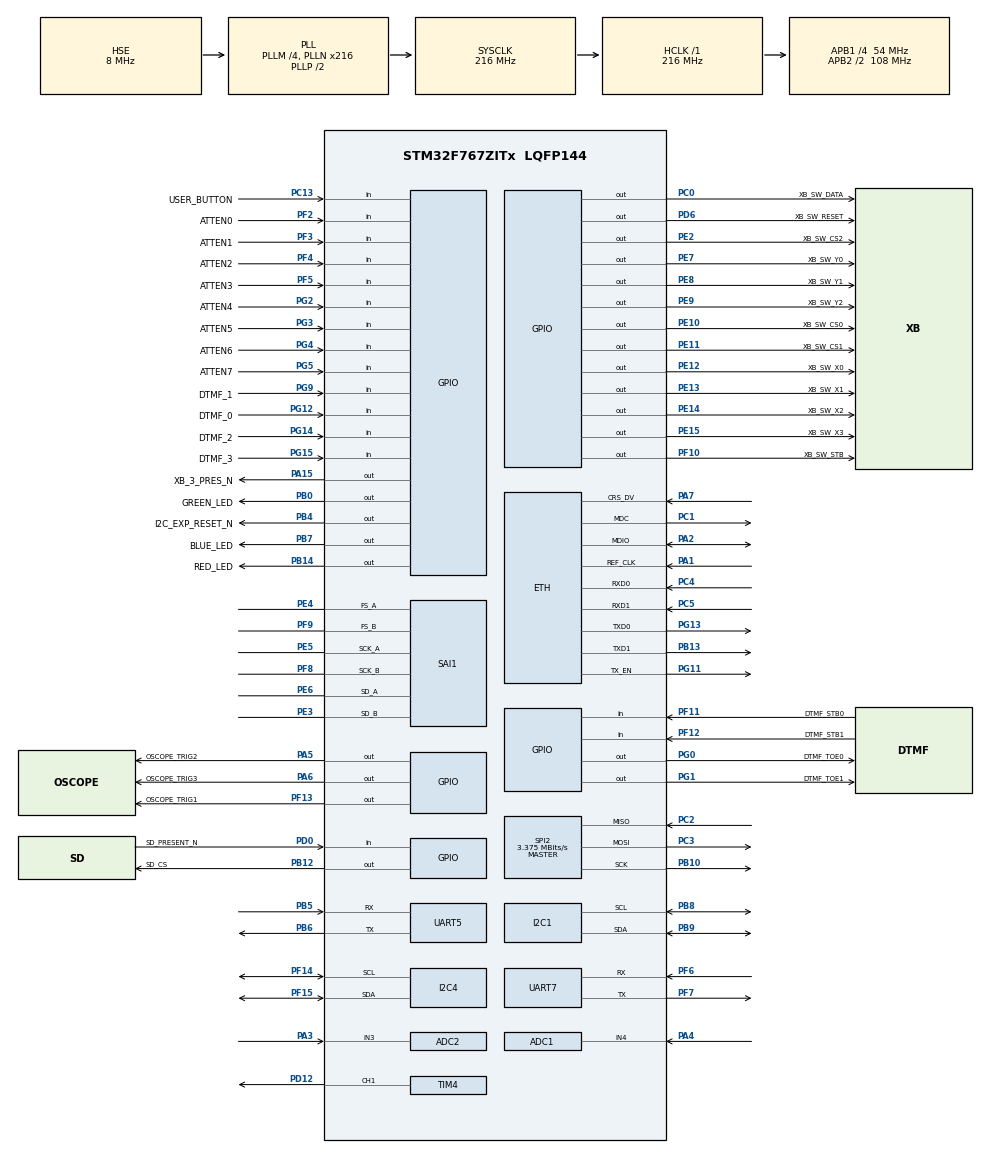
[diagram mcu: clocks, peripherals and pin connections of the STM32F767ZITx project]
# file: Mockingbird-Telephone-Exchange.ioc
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ADC1.Channel-1\#ChannelRegularConversion=ADC_CHANNEL_4
ADC1.DMAContinuousRequests=ENABLE
ADC1.EnableAnalogWatchDog=false
ADC1.ExternalTrigConv=ADC_EXTERNALTRIGCONV_T4_TRGO
ADC1.NbrOfConversionFlag=1
ADC1.Rank-1\#ChannelRegularConversion=1
ADC1.SamplingTime-1\#ChannelRegularConversion=ADC_SAMPLETIME_3CYCLES
ADC1.master=1
ADC2.Channel-0\#ChannelRegularConversion=ADC_CHANNEL_3
ADC2.DMAContinuousRequests=ENABLE
ADC2.EnableAnalogWatchDog=false
ADC2.ExternalTrigConv=ADC_EXTERNALTRIGCONV_T4_TRGO
ADC2.NbrOfConversionFlag=1
ADC2.Rank-0\#ChannelRegularConversion=1
ADC2.SamplingTime-0\#ChannelRegularConversion=ADC_SAMPLETIME_3CYCLES
Dma.ADC1.3.Direction=DMA_PERIPH_TO_MEMORY
Dma.ADC1.3.FIFOMode=DMA_FIFOMODE_DISABLE
Dma.ADC1.3.Instance=DMA2_Stream0
Dma.ADC1.3.MemDataAlignment=DMA_MDATAALIGN_HALFWORD
Dma.ADC1.3.MemInc=DMA_MINC_ENABLE
Dma.ADC1.3.Mode=DMA_CIRCULAR
Dma.ADC1.3.PeriphDataAlignment=DMA_PDATAALIGN_HALFWORD
Dma.ADC1.3.PeriphInc=DMA_PINC_DISABLE
Dma.ADC1.3.Priority=DMA_PRIORITY_LOW
Dma.ADC2.2.Direction=DMA_PERIPH_TO_MEMORY
Dma.ADC2.2.FIFOMode=DMA_FIFOMODE_DISABLE
Dma.ADC2.2.Instance=DMA2_Stream2
Dma.ADC2.2.MemDataAlignment=DMA_MDATAALIGN_HALFWORD
Dma.ADC2.2.MemInc=DMA_MINC_ENABLE
Dma.ADC2.2.Mode=DMA_CIRCULAR
Dma.ADC2.2.PeriphDataAlignment=DMA_PDATAALIGN_HALFWORD
Dma.ADC2.2.PeriphInc=DMA_PINC_DISABLE
Dma.ADC2.2.Priority=DMA_PRIORITY_LOW
Dma.I2C1_RX.4.Direction=DMA_PERIPH_TO_MEMORY
Dma.I2C1_RX.4.FIFOMode=DMA_FIFOMODE_DISABLE
Dma.I2C1_RX.4.Instance=DMA1_Stream0
Dma.I2C1_RX.4.MemDataAlignment=DMA_MDATAALIGN_BYTE
Dma.I2C1_RX.4.MemInc=DMA_MINC_ENABLE
Dma.I2C1_RX.4.Mode=DMA_NORMAL
Dma.I2C1_RX.4.PeriphDataAlignment=DMA_PDATAALIGN_BYTE
Dma.I2C1_RX.4.PeriphInc=DMA_PINC_DISABLE
Dma.I2C1_RX.4.Priority=DMA_PRIORITY_LOW
Dma.I2C1_TX.5.Direction=DMA_MEMORY_TO_PERIPH
Dma.I2C1_TX.5.FIFOMode=DMA_FIFOMODE_DISABLE
Dma.I2C1_TX.5.Instance=DMA1_Stream6
Dma.I2C1_TX.5.MemDataAlignment=DMA_MDATAALIGN_BYTE
Dma.I2C1_TX.5.MemInc=DMA_MINC_ENABLE
Dma.I2C1_TX.5.Mode=DMA_NORMAL
Dma.I2C1_TX.5.PeriphDataAlignment=DMA_PDATAALIGN_BYTE
Dma.I2C1_TX.5.PeriphInc=DMA_PINC_DISABLE
Dma.I2C1_TX.5.Priority=DMA_PRIORITY_LOW
Dma.Request0=SAI1_A
Dma.Request1=SAI1_B
Dma.Request2=ADC2
Dma.Request3=ADC1
Dma.Request4=I2C1_RX
Dma.Request5=I2C1_TX
Dma.SAI1_A.0.Direction=DMA_MEMORY_TO_PERIPH
Dma.SAI1_A.0.FIFOMode=DMA_FIFOMODE_DISABLE
Dma.SAI1_A.0.Instance=DMA2_Stream1
Dma.SAI1_A.0.MemDataAlignment=DMA_MDATAALIGN_HALFWORD
Dma.SAI1_A.0.MemInc=DMA_MINC_ENABLE
Dma.SAI1_A.0.Mode=DMA_CIRCULAR
Dma.SAI1_A.0.PeriphDataAlignment=DMA_PDATAALIGN_HALFWORD
Dma.SAI1_A.0.PeriphInc=DMA_PINC_DISABLE
Dma.SAI1_A.0.Priority=DMA_PRIORITY_HIGH
Dma.SAI1_B.1.Direction=DMA_MEMORY_TO_PERIPH
Dma.SAI1_B.1.FIFOMode=DMA_FIFOMODE_DISABLE
Dma.SAI1_B.1.Instance=DMA2_Stream4
Dma.SAI1_B.1.MemDataAlignment=DMA_MDATAALIGN_HALFWORD
Dma.SAI1_B.1.MemInc=DMA_MINC_ENABLE
Dma.SAI1_B.1.Mode=DMA_CIRCULAR
Dma.SAI1_B.1.PeriphDataAlignment=DMA_PDATAALIGN_HALFWORD
Dma.SAI1_B.1.PeriphInc=DMA_PINC_DISABLE
Dma.SAI1_B.1.Priority=DMA_PRIORITY_HIGH
ETH.MediaInterface=HAL_ETH_RMII_MODE
FATFS._FS_LOCK=8
FATFS._FS_RPATH=2
FATFS._MAX_LFN=32
FATFS._USE_LFN=2
FREERTOS.Tasks01=defaultTask,24,2048,StartDefaultTask,Default,NULL,Dynamic,NULL,NULL
FREERTOS.configENABLE_FPU=0
FREERTOS.configRECORD_STACK_HIGH_ADDRESS=0
FREERTOS.configTOTAL_HEAP_SIZE=65536
FREERTOS.configUSE_NEWLIB_REENTRANT=1
I2C1.Timing=0x20404768
I2C4.Timing=0x20404768
Mcu.Family=STM32F7
Mcu.Name=STM32F767ZITx
Mcu.Package=LQFP144
NVIC.DMA1_Stream0_IRQn=true\:5\:0\:false\:false\:true\:true\:false\:true\:true
NVIC.DMA1_Stream6_IRQn=true\:5\:0\:false\:false\:true\:true\:false\:true\:true
NVIC.DMA2_Stream0_IRQn=true\:5\:0\:false\:false\:true\:true\:false\:true\:true
NVIC.DMA2_Stream1_IRQn=true\:5\:0\:false\:false\:true\:true\:false\:true\:true
NVIC.DMA2_Stream2_IRQn=true\:5\:0\:false\:false\:true\:true\:false\:true\:true
NVIC.DMA2_Stream4_IRQn=true\:5\:0\:false\:false\:true\:true\:false\:true\:true
NVIC.I2C1_ER_IRQn=true\:5\:0\:false\:false\:true\:true\:true\:true\:true
NVIC.I2C1_EV_IRQn=true\:5\:0\:false\:false\:true\:true\:true\:true\:true
NVIC.PriorityGroup=NVIC_PRIORITYGROUP_4
NVIC.TIM1_UP_TIM10_IRQn=true\:15\:0\:false\:false\:true\:false\:false\:true\:true
NVIC.TimeBase=TIM1_UP_TIM10_IRQn
NVIC.TimeBaseIP=TIM10
NVIC.UART5_IRQn=true\:5\:0\:false\:false\:true\:true\:true\:true\:true
NVIC.UART7_IRQn=true\:5\:0\:false\:false\:true\:true\:true\:true\:true
PA1.Mode=RMII
PA1.Signal=ETH_REF_CLK
PA13.Mode=Serial_Wire
PA13.Signal=SYS_JTMS-SWDIO
PA14.Mode=Serial_Wire
PA14.Signal=SYS_JTCK-SWCLK
PA15.GPIO_Label=XB_3_PRES_N
PA15.Signal=GPIO_Output
PA2.Mode=RMII
PA2.Signal=ETH_MDIO
PA3.Signal=ADCx_IN3
PA4.Signal=ADCx_IN4
PA5.GPIO_Label=OSCOPE_TRIG2
PA5.Signal=GPIO_Output
PA6.GPIO_Label=OSCOPE_TRIG3
PA6.Signal=GPIO_Output
PA7.Mode=RMII
PA7.Signal=ETH_CRS_DV
PB0.GPIO_Label=GREEN_LED
PB0.Signal=GPIO_Output
PB10.Mode=Full_Duplex_Master
PB10.Signal=SPI2_SCK
PB12.GPIO_Label=SD_CS
PB12.Signal=GPIO_Output
PB13.Mode=RMII
PB13.Signal=ETH_TXD1
PB14.GPIO_Label=RED_LED
PB14.Signal=GPIO_Output
PB4.GPIO_Label=I2C_EXP_RESET_N
PB4.Signal=GPIO_Output
PB5.Mode=Asynchronous
PB5.Signal=UART5_RX
PB6.Mode=Asynchronous
PB6.Signal=UART5_TX
PB7.GPIO_Label=BLUE_LED
PB7.Signal=GPIO_Output
PB8.Mode=I2C
PB8.Signal=I2C1_SCL
PB9.Mode=I2C
PB9.Signal=I2C1_SDA
PC0.GPIO_Label=XB_SW_DATA
PC0.Signal=GPIO_Output
PC1.Mode=RMII
PC1.Signal=ETH_MDC
PC13.GPIO_Label=USER_BUTTON
PC13.GPIO_PuPd=GPIO_NOPULL
PC13.Signal=GPIO_Input
PC14/OSC32_IN.Mode=LSE-External-Oscillator
PC14/OSC32_IN.Signal=RCC_OSC32_IN
PC15/OSC32_OUT.Mode=LSE-External-Oscillator
PC15/OSC32_OUT.Signal=RCC_OSC32_OUT
PC2.Mode=Full_Duplex_Master
PC2.Signal=SPI2_MISO
PC3.Mode=Full_Duplex_Master
PC3.Signal=SPI2_MOSI
PC4.Mode=RMII
PC4.Signal=ETH_RXD0
PC5.Mode=RMII
PC5.Signal=ETH_RXD1
PD0.GPIO_Label=SD_PRESENT_N
PD0.GPIO_PuPd=GPIO_PULLUP
PD0.Signal=GPIO_Input
PD12.Signal=S_TIM4_CH1
PD6.GPIO_Label=XB_SW_RESET
PD6.Signal=GPIO_Output
PE10.GPIO_Label=XB_SW_CS0
PE10.Signal=GPIO_Output
PE11.GPIO_Label=XB_SW_CS1
PE11.Signal=GPIO_Output
PE12.GPIO_Label=XB_SW_X0
PE12.Signal=GPIO_Output
PE13.GPIO_Label=XB_SW_X1
PE13.Signal=GPIO_Output
PE14.GPIO_Label=XB_SW_X2
PE14.Signal=GPIO_Output
PE15.GPIO_Label=XB_SW_X3
PE15.Signal=GPIO_Output
PE2.GPIO_Label=XB_SW_CS2
PE2.Signal=GPIO_Output
PE3.Mode=SAI_B_Master
PE3.Signal=SAI1_SD_B
PE4.Mode=SAI_A_Master
PE4.Signal=SAI1_FS_A
PE5.Mode=SAI_A_Master
PE5.Signal=SAI1_SCK_A
PE6.Mode=SAI_A_Master
PE6.Signal=SAI1_SD_A
PE7.GPIO_Label=XB_SW_Y0
PE7.Signal=GPIO_Output
PE8.GPIO_Label=XB_SW_Y1
PE8.Signal=GPIO_Output
PE9.GPIO_Label=XB_SW_Y2
PE9.Signal=GPIO_Output
PF10.GPIO_Label=XB_SW_STB
PF10.Signal=GPIO_Output
PF11.GPIO_Label=DTMF_STB0
PF11.Signal=GPIO_Input
PF12.GPIO_Label=DTMF_STB1
PF12.Signal=GPIO_Input
PF13.GPIO_Label=OSCOPE_TRIG1
PF13.Signal=GPIO_Output
PF14.Mode=I2C
PF14.Signal=I2C4_SCL
PF15.Mode=I2C
PF15.Signal=I2C4_SDA
PF2.GPIO_Label=ATTEN0
PF2.GPIO_PuPd=GPIO_PULLDOWN
PF2.Signal=GPIO_Input
PF3.GPIO_Label=ATTEN1
PF3.GPIO_PuPd=GPIO_PULLDOWN
PF3.Signal=GPIO_Input
PF4.GPIO_Label=ATTEN2
PF4.GPIO_PuPd=GPIO_PULLDOWN
PF4.Signal=GPIO_Input
PF5.GPIO_Label=ATTEN3
PF5.GPIO_PuPd=GPIO_PULLDOWN
PF5.Signal=GPIO_Input
PF6.Mode=Asynchronous
PF6.Signal=UART7_RX
PF7.Mode=Asynchronous
PF7.Signal=UART7_TX
PF8.Mode=SAI_B_Master
PF8.Signal=SAI1_SCK_B
PF9.Mode=SAI_B_Master
PF9.Signal=SAI1_FS_B
PG0.GPIO_Label=DTMF_TOE0
PG0.Signal=GPIO_Output
PG1.GPIO_Label=DTMF_TOE1
PG1.Signal=GPIO_Output
PG11.Mode=RMII
PG11.Signal=ETH_TX_EN
PG12.GPIO_Label=DTMF_0
PG12.GPIO_PuPd=GPIO_PULLDOWN
PG12.Signal=GPIO_Input
PG13.Mode=RMII
PG13.Signal=ETH_TXD0
PG14.GPIO_Label=DTMF_2
PG14.GPIO_PuPd=GPIO_PULLDOWN
PG14.Signal=GPIO_Input
PG15.GPIO_Label=DTMF_3
PG15.GPIO_PuPd=GPIO_PULLDOWN
PG15.Signal=GPIO_Input
PG2.GPIO_Label=ATTEN4
PG2.GPIO_PuPd=GPIO_PULLDOWN
PG2.Signal=GPIO_Input
PG3.GPIO_Label=ATTEN5
PG3.GPIO_PuPd=GPIO_PULLDOWN
PG3.Signal=GPIO_Input
PG4.GPIO_Label=ATTEN6
PG4.GPIO_PuPd=GPIO_PULLDOWN
PG4.Signal=GPIO_Input
PG5.GPIO_Label=ATTEN7
PG5.GPIO_PuPd=GPIO_PULLDOWN
PG5.Signal=GPIO_Input
PG9.GPIO_Label=DTMF_1
PG9.Signal=GPIO_Input
PH0/OSC_IN.Mode=HSE-External-Oscillator
PH0/OSC_IN.Signal=RCC_OSC_IN
PH1/OSC_OUT.Mode=HSE-External-Oscillator
PH1/OSC_OUT.Signal=RCC_OSC_OUT
ProjectManager.HeapSize=0x200
ProjectManager.StackSize=0x400
ProjectManager.TargetToolchain=STM32CubeIDE
RCC.AHBFreq_Value=216000000
RCC.APB1CLKDivider=RCC_HCLK_DIV4
RCC.APB1Freq_Value=54000000
RCC.APB1TimFreq_Value=108000000
RCC.APB2CLKDivider=RCC_HCLK_DIV2
RCC.APB2Freq_Value=108000000
RCC.APB2TimFreq_Value=216000000
RCC.CortexFreq_Value=216000000
RCC.HCLKFreq_Value=216000000
RCC.HSE_VALUE=8000000
RCC.HSI_VALUE=16000000
RCC.PLLI2SN=136
RCC.PLLI2SQ=3
RCC.PLLI2SQDiv=2
RCC.PLLM=4
RCC.PLLN=216
RCC.PLLQ=9
RCC.PLLSAIN=123
RCC.PLLSAIQ=4
RCC.PLLSAIQDiv=3
RCC.PLLSourceVirtual=RCC_PLLSOURCE_HSE
RCC.SDMMCClockSelection=RCC_SDMMC1CLKSOURCE_CLK48
RCC.SYSCLKFreq_VALUE=216000000
RCC.SYSCLKSource=RCC_SYSCLKSOURCE_PLLCLK
RCC.USBFreq_Value=48000000
RCC.VCOOutputFreq_Value=432000000
SAI1.AudioFrequency-SAI_A_Master=SAI_AUDIO_FREQUENCY_8K
SAI1.AudioFrequency-SAI_B_Master=SAI_AUDIO_FREQUENCY_8K
SAI1.ErrorAudioFreq-SAI_A_Master=0.08 %
SAI1.ErrorAudioFreq-SAI_B_Master=0.08 %
SAI1.InitProtocol-SAI_A_Master=Enable
SAI1.InitProtocol-SAI_B_Master=Enable
SAI1.Instance-SAI_A_Master=SAI$Index_Block_A
SAI1.Instance-SAI_B_Master=SAI$Index_Block_B
SAI1.MClockEnable-SAI_A_Master=SAI_MASTERCLOCK_DISABLE
SAI1.MClockEnable-SAI_B_Master=SAI_MASTERCLOCK_DISABLE
SAI1.RealAudioFreq-SAI_A_Master=8.007 KHz
SAI1.RealAudioFreq-SAI_B_Master=8.007 KHz
SAI1.VirtualMode-SAI_A_Master=VM_MASTER
SAI1.VirtualMode-SAI_B_Master=VM_MASTER
SAI1.VirtualProtocol-SAI_A_BASIC=VM_BASIC_PROTOCOL
SAI1.VirtualProtocol-SAI_B_BASIC=VM_BASIC_PROTOCOL
SH.ADCx_IN3.0=ADC2_IN3,IN3
SH.ADCx_IN4.0=ADC1_IN4,IN4
SH.S_TIM4_CH1.0=TIM4_CH1,Output Compare1 CH1
SPI2.BaudRatePrescaler=SPI_BAUDRATEPRESCALER_16
SPI2.CalculateBaudRate=3.375 MBits/s
SPI2.DataSize=SPI_DATASIZE_8BIT
SPI2.Direction=SPI_DIRECTION_2LINES
SPI2.Mode=SPI_MODE_MASTER
SPI2.NSSPMode=SPI_NSS_PULSE_DISABLE
SPI2.VirtualType=VM_MASTER
TIM4.Channel-Output\ Compare1\ CH1=TIM_CHANNEL_1
TIM4.OCMode_1=TIM_OCMODE_TOGGLE
TIM4.Period=125-1
TIM4.Prescaler=54-1
TIM4.TIM_MasterOutputTrigger=TIM_TRGO_UPDATE
UART5.OverrunDisableParam=UART_ADVFEATURE_OVERRUN_DISABLE
UART7.OverrunDisableParam=UART_ADVFEATURE_OVERRUN_DISABLE
VP_FATFS_VS_Generic.Mode=User_defined
VP_FREERTOS_VS_CMSIS_V2.Mode=CMSIS_V2
VP_SAI1_VP_$IpInstance_SAIA_SAI_BASIC.Mode=SAI_A_BASIC
VP_SAI1_VP_$IpInstance_SAIB_SAI_BASIC.Mode=SAI_B_BASIC
VP_SYS_VS_tim10.Mode=TIM10
VP_TIM4_VS_ClockSourceINT.Mode=Internal
board=custom

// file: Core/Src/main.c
/* USER CODE BEGIN Header */
/**
  ******************************************************************************
  * @file           : main.c
  * @brief          : Main program body
  ******************************************************************************
  * @attention
  *
  * Copyright (c) 2024 STMicroelectronics.
  * All rights reserved.
  *
  * This software is licensed under terms that can be found in the LICENSE file
  * in the root directory of this software component.
  * If no LICENSE file comes with this software, it is provided AS-IS.
  *
  ******************************************************************************
  */
/* USER CODE END Header */
#include "main.h"
#include "string.h"
#include "cmsis_os.h"
#include "fatfs.h"

/* USER CODE BEGIN Includes */
#include "top.h"

/* USER CODE END Includes */

#if defined ( __ICCARM__ ) /*!< IAR Compiler */
#pragma location=0x2007c000
ETH_DMADescTypeDef  DMARxDscrTab[ETH_RX_DESC_CNT]; /* Ethernet Rx DMA Descriptors */
#pragma location=0x2007c0a0
ETH_DMADescTypeDef  DMATxDscrTab[ETH_TX_DESC_CNT]; /* Ethernet Tx DMA Descriptors */

#elif defined ( __CC_ARM )  /* MDK ARM Compiler */

__attribute__((at(0x2007c000))) ETH_DMADescTypeDef  DMARxDscrTab[ETH_RX_DESC_CNT]; /* Ethernet Rx DMA Descriptors */
__attribute__((at(0x2007c0a0))) ETH_DMADescTypeDef  DMATxDscrTab[ETH_TX_DESC_CNT]; /* Ethernet Tx DMA Descriptors */

#elif defined ( __GNUC__ ) /* GNU Compiler */
ETH_DMADescTypeDef DMARxDscrTab[ETH_RX_DESC_CNT] __attribute__((section(".RxDecripSection"))); /* Ethernet Rx DMA Descriptors */
ETH_DMADescTypeDef DMATxDscrTab[ETH_TX_DESC_CNT] __attribute__((section(".TxDecripSection")));   /* Ethernet Tx DMA Descriptors */

#endif

ETH_TxPacketConfig TxConfig;

ADC_HandleTypeDef hadc1;
ADC_HandleTypeDef hadc2;
DMA_HandleTypeDef hdma_adc1;
DMA_HandleTypeDef hdma_adc2;

ETH_HandleTypeDef heth;

I2C_HandleTypeDef hi2c1;
I2C_HandleTypeDef hi2c4;
DMA_HandleTypeDef hdma_i2c1_rx;
DMA_HandleTypeDef hdma_i2c1_tx;

SAI_HandleTypeDef hsai_BlockA1;
SAI_HandleTypeDef hsai_BlockB1;
DMA_HandleTypeDef hdma_sai1_a;
DMA_HandleTypeDef hdma_sai1_b;

SPI_HandleTypeDef hspi2;

TIM_HandleTypeDef htim4;

UART_HandleTypeDef huart5;
UART_HandleTypeDef huart7;

/* Definitions for defaultTask */
osThreadId_t defaultTaskHandle;
const osThreadAttr_t defaultTask_attributes = {
  .name = "defaultTask",
  .stack_size = 2048 * 4,
  .priority = (osPriority_t) osPriorityNormal,
};

void SystemClock_Config(void);
void PeriphCommonClock_Config(void);
static void MX_GPIO_Init(void);
static void MX_DMA_Init(void);
static void MX_SAI1_Init(void);
static void MX_I2C1_Init(void);
static void MX_ADC1_Init(void);
static void MX_ADC2_Init(void);
static void MX_UART5_Init(void);
static void MX_I2C4_Init(void);
static void MX_UART7_Init(void);
static void MX_TIM4_Init(void);
static void MX_ETH_Init(void);
static void MX_SPI2_Init(void);
void StartDefaultTask(void *argument);

int main(void)
{

  /* MCU Configuration--------------------------------------------------------*/

  /* Reset of all peripherals, Initializes the Flash interface and the Systick. */
  HAL_Init();

  /* Configure the system clock */
  SystemClock_Config();

/* Configure the peripherals common clocks */
  PeriphCommonClock_Config();

  /* Initialize all configured peripherals */
  MX_GPIO_Init();
  MX_DMA_Init();
  MX_SAI1_Init();
  MX_I2C1_Init();
  MX_ADC1_Init();
  MX_ADC2_Init();
  MX_UART5_Init();
  MX_I2C4_Init();
  MX_UART7_Init();
  MX_TIM4_Init();
  MX_ETH_Init();
  MX_FATFS_Init();
  MX_SPI2_Init();

  /* Init scheduler */
  osKernelInitialize();

  /* Create the thread(s) */
  /* creation of defaultTask */
  defaultTaskHandle = osThreadNew(StartDefaultTask, NULL, &defaultTask_attributes);

  /* USER CODE BEGIN RTOS_EVENTS */
  /* Setup hook */
  Top_setup();
  /* add events, ... */
  /* USER CODE END RTOS_EVENTS */

  /* Start scheduler */
  osKernelStart();

  /* We should never get here as control is now taken by the scheduler */
  /* Infinite loop */
  while (1)
  {

  }
}

void SystemClock_Config(void)
{
  RCC_OscInitTypeDef RCC_OscInitStruct = {0};
  RCC_ClkInitTypeDef RCC_ClkInitStruct = {0};

  /** Configure LSE Drive Capability
  */
  HAL_PWR_EnableBkUpAccess();

  /** Configure the main internal regulator output voltage
  */
  __HAL_RCC_PWR_CLK_ENABLE();
  __HAL_PWR_VOLTAGESCALING_CONFIG(PWR_REGULATOR_VOLTAGE_SCALE1);

  /** Initializes the RCC Oscillators according to the specified parameters
  * in the RCC_OscInitTypeDef structure.
  */
  RCC_OscInitStruct.OscillatorType = RCC_OSCILLATORTYPE_HSE;
  RCC_OscInitStruct.HSEState = RCC_HSE_ON;
  RCC_OscInitStruct.PLL.PLLState = RCC_PLL_ON;
  RCC_OscInitStruct.PLL.PLLSource = RCC_PLLSOURCE_HSE;
  RCC_OscInitStruct.PLL.PLLM = 4;
  RCC_OscInitStruct.PLL.PLLN = 216;
  RCC_OscInitStruct.PLL.PLLP = RCC_PLLP_DIV2;
  RCC_OscInitStruct.PLL.PLLQ = 9;
  RCC_OscInitStruct.PLL.PLLR = 2;
  if (HAL_RCC_OscConfig(&RCC_OscInitStruct) != HAL_OK)
  {
    Error_Handler();
  }

  /** Activate the Over-Drive mode
  */
  if (HAL_PWREx_EnableOverDrive() != HAL_OK)
  {
    Error_Handler();
  }

  /** Initializes the CPU, AHB and APB buses clocks
  */
  RCC_ClkInitStruct.ClockType = RCC_CLOCKTYPE_HCLK|RCC_CLOCKTYPE_SYSCLK
                              |RCC_CLOCKTYPE_PCLK1|RCC_CLOCKTYPE_PCLK2;
  RCC_ClkInitStruct.SYSCLKSource = RCC_SYSCLKSOURCE_PLLCLK;
  RCC_ClkInitStruct.AHBCLKDivider = RCC_SYSCLK_DIV1;
  RCC_ClkInitStruct.APB1CLKDivider = RCC_HCLK_DIV4;
  RCC_ClkInitStruct.APB2CLKDivider = RCC_HCLK_DIV2;

  if (HAL_RCC_ClockConfig(&RCC_ClkInitStruct, FLASH_LATENCY_7) != HAL_OK)
  {
    Error_Handler();
  }
}

void PeriphCommonClock_Config(void)
{
  RCC_PeriphCLKInitTypeDef PeriphClkInitStruct = {0};

  /** Initializes the peripherals clock
  */
  PeriphClkInitStruct.PeriphClockSelection = RCC_PERIPHCLK_SAI1;
  PeriphClkInitStruct.PLLSAI.PLLSAIN = 123;
  PeriphClkInitStruct.PLLSAI.PLLSAIR = 2;
  PeriphClkInitStruct.PLLSAI.PLLSAIQ = 4;
  PeriphClkInitStruct.PLLSAI.PLLSAIP = RCC_PLLSAIP_DIV2;
  PeriphClkInitStruct.PLLSAIDivQ = 3;
  PeriphClkInitStruct.PLLSAIDivR = RCC_PLLSAIDIVR_2;
  PeriphClkInitStruct.Sai1ClockSelection = RCC_SAI1CLKSOURCE_PLLSAI;
  if (HAL_RCCEx_PeriphCLKConfig(&PeriphClkInitStruct) != HAL_OK)
  {
    Error_Handler();
  }
}

static void MX_ADC1_Init(void)
{

  ADC_ChannelConfTypeDef sConfig = {0};

  /** Configure the global features of the ADC (Clock, Resolution, Data Alignment and number of conversion)
  */
  hadc1.Instance = ADC1;
  hadc1.Init.ClockPrescaler = ADC_CLOCK_SYNC_PCLK_DIV4;
  hadc1.Init.Resolution = ADC_RESOLUTION_12B;
  hadc1.Init.ScanConvMode = ADC_SCAN_DISABLE;
  hadc1.Init.ContinuousConvMode = DISABLE;
  hadc1.Init.DiscontinuousConvMode = DISABLE;
  hadc1.Init.ExternalTrigConvEdge = ADC_EXTERNALTRIGCONVEDGE_RISING;
  hadc1.Init.ExternalTrigConv = ADC_EXTERNALTRIGCONV_T4_TRGO;
  hadc1.Init.DataAlign = ADC_DATAALIGN_RIGHT;
  hadc1.Init.NbrOfConversion = 1;
  hadc1.Init.DMAContinuousRequests = ENABLE;
  hadc1.Init.EOCSelection = ADC_EOC_SINGLE_CONV;
  if (HAL_ADC_Init(&hadc1) != HAL_OK)
  {
    Error_Handler();
  }

  /** Configure for the selected ADC regular channel its corresponding rank in the sequencer and its sample time.
  */
  sConfig.Channel = ADC_CHANNEL_4;
  sConfig.Rank = ADC_REGULAR_RANK_1;
  sConfig.SamplingTime = ADC_SAMPLETIME_3CYCLES;
  if (HAL_ADC_ConfigChannel(&hadc1, &sConfig) != HAL_OK)
  {
    Error_Handler();
  }

}

static void MX_ADC2_Init(void)
{

  ADC_ChannelConfTypeDef sConfig = {0};

  /** Configure the global features of the ADC (Clock, Resolution, Data Alignment and number of conversion)
  */
  hadc2.Instance = ADC2;
  hadc2.Init.ClockPrescaler = ADC_CLOCK_SYNC_PCLK_DIV4;
  hadc2.Init.Resolution = ADC_RESOLUTION_12B;
  hadc2.Init.ScanConvMode = ADC_SCAN_DISABLE;
  hadc2.Init.ContinuousConvMode = DISABLE;
  hadc2.Init.DiscontinuousConvMode = DISABLE;
  hadc2.Init.ExternalTrigConvEdge = ADC_EXTERNALTRIGCONVEDGE_RISING;
  hadc2.Init.ExternalTrigConv = ADC_EXTERNALTRIGCONV_T4_TRGO;
  hadc2.Init.DataAlign = ADC_DATAALIGN_RIGHT;
  hadc2.Init.NbrOfConversion = 1;
  hadc2.Init.DMAContinuousRequests = ENABLE;
  hadc2.Init.EOCSelection = ADC_EOC_SINGLE_CONV;
  if (HAL_ADC_Init(&hadc2) != HAL_OK)
  {
    Error_Handler();
  }

  /** Configure for the selected ADC regular channel its corresponding rank in the sequencer and its sample time.
  */
  sConfig.Channel = ADC_CHANNEL_3;
  sConfig.Rank = ADC_REGULAR_RANK_1;
  sConfig.SamplingTime = ADC_SAMPLETIME_3CYCLES;
  if (HAL_ADC_ConfigChannel(&hadc2, &sConfig) != HAL_OK)
  {
    Error_Handler();
  }

}

static void MX_ETH_Init(void)
{

   static uint8_t MACAddr[6];

  heth.Instance = ETH;
  MACAddr[0] = 0x00;
  MACAddr[1] = 0x80;
  MACAddr[2] = 0xE1;
  MACAddr[3] = 0x00;
  MACAddr[4] = 0x00;
  MACAddr[5] = 0x00;
  heth.Init.MACAddr = &MACAddr[0];
  heth.Init.MediaInterface = HAL_ETH_RMII_MODE;
  heth.Init.TxDesc = DMATxDscrTab;
  heth.Init.RxDesc = DMARxDscrTab;
  heth.Init.RxBuffLen = 1524;

  if (HAL_ETH_Init(&heth) != HAL_OK)
  {
    Error_Handler();
  }

  memset(&TxConfig, 0 , sizeof(ETH_TxPacketConfig));
  TxConfig.Attributes = ETH_TX_PACKETS_FEATURES_CSUM | ETH_TX_PACKETS_FEATURES_CRCPAD;
  TxConfig.ChecksumCtrl = ETH_CHECKSUM_IPHDR_PAYLOAD_INSERT_PHDR_CALC;
  TxConfig.CRCPadCtrl = ETH_CRC_PAD_INSERT;

}

static void MX_I2C1_Init(void)
{

  hi2c1.Instance = I2C1;
  hi2c1.Init.Timing = 0x20404768;
  hi2c1.Init.OwnAddress1 = 0;
  hi2c1.Init.AddressingMode = I2C_ADDRESSINGMODE_7BIT;
  hi2c1.Init.DualAddressMode = I2C_DUALADDRESS_DISABLE;
  hi2c1.Init.OwnAddress2 = 0;
  hi2c1.Init.OwnAddress2Masks = I2C_OA2_NOMASK;
  hi2c1.Init.GeneralCallMode = I2C_GENERALCALL_DISABLE;
  hi2c1.Init.NoStretchMode = I2C_NOSTRETCH_DISABLE;
  if (HAL_I2C_Init(&hi2c1) != HAL_OK)
  {
    Error_Handler();
  }

  /** Configure Analogue filter
  */
  if (HAL_I2CEx_ConfigAnalogFilter(&hi2c1, I2C_ANALOGFILTER_ENABLE) != HAL_OK)
  {
    Error_Handler();
  }

  /** Configure Digital filter
  */
  if (HAL_I2CEx_ConfigDigitalFilter(&hi2c1, 0) != HAL_OK)
  {
    Error_Handler();
  }

}

static void MX_I2C4_Init(void)
{

  hi2c4.Instance = I2C4;
  hi2c4.Init.Timing = 0x20404768;
  hi2c4.Init.OwnAddress1 = 0;
  hi2c4.Init.AddressingMode = I2C_ADDRESSINGMODE_7BIT;
  hi2c4.Init.DualAddressMode = I2C_DUALADDRESS_DISABLE;
  hi2c4.Init.OwnAddress2 = 0;
  hi2c4.Init.OwnAddress2Masks = I2C_OA2_NOMASK;
  hi2c4.Init.GeneralCallMode = I2C_GENERALCALL_DISABLE;
  hi2c4.Init.NoStretchMode = I2C_NOSTRETCH_DISABLE;
  if (HAL_I2C_Init(&hi2c4) != HAL_OK)
  {
    Error_Handler();
  }

  /** Configure Analogue filter
  */
  if (HAL_I2CEx_ConfigAnalogFilter(&hi2c4, I2C_ANALOGFILTER_ENABLE) != HAL_OK)
  {
    Error_Handler();
  }

  /** Configure Digital filter
  */
  if (HAL_I2CEx_ConfigDigitalFilter(&hi2c4, 0) != HAL_OK)
  {
    Error_Handler();
  }

}

static void MX_SAI1_Init(void)
{

  hsai_BlockA1.Instance = SAI1_Block_A;
  hsai_BlockA1.Init.AudioMode = SAI_MODEMASTER_TX;
  hsai_BlockA1.Init.Synchro = SAI_ASYNCHRONOUS;
  hsai_BlockA1.Init.OutputDrive = SAI_OUTPUTDRIVE_DISABLE;
  hsai_BlockA1.Init.NoDivider = SAI_MASTERDIVIDER_ENABLE;
  hsai_BlockA1.Init.FIFOThreshold = SAI_FIFOTHRESHOLD_EMPTY;
  hsai_BlockA1.Init.AudioFrequency = SAI_AUDIO_FREQUENCY_8K;
  hsai_BlockA1.Init.SynchroExt = SAI_SYNCEXT_DISABLE;
  hsai_BlockA1.Init.MonoStereoMode = SAI_STEREOMODE;
  hsai_BlockA1.Init.CompandingMode = SAI_NOCOMPANDING;
  hsai_BlockA1.Init.TriState = SAI_OUTPUT_NOTRELEASED;
  if (HAL_SAI_InitProtocol(&hsai_BlockA1, SAI_I2S_STANDARD, SAI_PROTOCOL_DATASIZE_16BIT, 2) != HAL_OK)
  {
    Error_Handler();
  }
  hsai_BlockB1.Instance = SAI1_Block_B;
  hsai_BlockB1.Init.AudioMode = SAI_MODEMASTER_TX;
  hsai_BlockB1.Init.Synchro = SAI_ASYNCHRONOUS;
  hsai_BlockB1.Init.OutputDrive = SAI_OUTPUTDRIVE_DISABLE;
  hsai_BlockB1.Init.NoDivider = SAI_MASTERDIVIDER_ENABLE;
  hsai_BlockB1.Init.FIFOThreshold = SAI_FIFOTHRESHOLD_EMPTY;
  hsai_BlockB1.Init.AudioFrequency = SAI_AUDIO_FREQUENCY_8K;
  hsai_BlockB1.Init.SynchroExt = SAI_SYNCEXT_DISABLE;
  hsai_BlockB1.Init.MonoStereoMode = SAI_STEREOMODE;
  hsai_BlockB1.Init.CompandingMode = SAI_NOCOMPANDING;
  hsai_BlockB1.Init.TriState = SAI_OUTPUT_NOTRELEASED;
  if (HAL_SAI_InitProtocol(&hsai_BlockB1, SAI_I2S_STANDARD, SAI_PROTOCOL_DATASIZE_16BIT, 2) != HAL_OK)
  {
    Error_Handler();
  }

}

static void MX_SPI2_Init(void)
{

  /* SPI2 parameter configuration*/
  hspi2.Instance = SPI2;
  hspi2.Init.Mode = SPI_MODE_MASTER;
  hspi2.Init.Direction = SPI_DIRECTION_2LINES;
  hspi2.Init.DataSize = SPI_DATASIZE_8BIT;
  hspi2.Init.CLKPolarity = SPI_POLARITY_LOW;
  hspi2.Init.CLKPhase = SPI_PHASE_1EDGE;
  hspi2.Init.NSS = SPI_NSS_SOFT;
  hspi2.Init.BaudRatePrescaler = SPI_BAUDRATEPRESCALER_16;
  hspi2.Init.FirstBit = SPI_FIRSTBIT_MSB;
  hspi2.Init.TIMode = SPI_TIMODE_DISABLE;
  hspi2.Init.CRCCalculation = SPI_CRCCALCULATION_DISABLE;
  hspi2.Init.CRCPolynomial = 7;
  hspi2.Init.CRCLength = SPI_CRC_LENGTH_DATASIZE;
  hspi2.Init.NSSPMode = SPI_NSS_PULSE_DISABLE;
  if (HAL_SPI_Init(&hspi2) != HAL_OK)
  {
    Error_Handler();
  }

}

static void MX_TIM4_Init(void)
{

  TIM_ClockConfigTypeDef sClockSourceConfig = {0};
  TIM_MasterConfigTypeDef sMasterConfig = {0};
  TIM_OC_InitTypeDef sConfigOC = {0};

  htim4.Instance = TIM4;
  htim4.Init.Prescaler = 54-1;
  htim4.Init.CounterMode = TIM_COUNTERMODE_UP;
  htim4.Init.Period = 125-1;
  htim4.Init.ClockDivision = TIM_CLOCKDIVISION_DIV1;
  htim4.Init.AutoReloadPreload = TIM_AUTORELOAD_PRELOAD_DISABLE;
  if (HAL_TIM_Base_Init(&htim4) != HAL_OK)
  {
    Error_Handler();
  }
  sClockSourceConfig.ClockSource = TIM_CLOCKSOURCE_INTERNAL;
  if (HAL_TIM_ConfigClockSource(&htim4, &sClockSourceConfig) != HAL_OK)
  {
    Error_Handler();
  }
  if (HAL_TIM_OC_Init(&htim4) != HAL_OK)
  {
    Error_Handler();
  }
  sMasterConfig.MasterOutputTrigger = TIM_TRGO_UPDATE;
  sMasterConfig.MasterSlaveMode = TIM_MASTERSLAVEMODE_DISABLE;
  if (HAL_TIMEx_MasterConfigSynchronization(&htim4, &sMasterConfig) != HAL_OK)
  {
    Error_Handler();
  }
  sConfigOC.OCMode = TIM_OCMODE_TOGGLE;
  sConfigOC.Pulse = 0;
  sConfigOC.OCPolarity = TIM_OCPOLARITY_HIGH;
  sConfigOC.OCFastMode = TIM_OCFAST_DISABLE;
  if (HAL_TIM_OC_ConfigChannel(&htim4, &sConfigOC, TIM_CHANNEL_1) != HAL_OK)
  {
    Error_Handler();
  }
  HAL_TIM_MspPostInit(&htim4);

}

static void MX_UART5_Init(void)
{

  huart5.Instance = UART5;
  huart5.Init.BaudRate = 115200;
  huart5.Init.WordLength = UART_WORDLENGTH_8B;
  huart5.Init.StopBits = UART_STOPBITS_1;
  huart5.Init.Parity = UART_PARITY_NONE;
  huart5.Init.Mode = UART_MODE_TX_RX;
  huart5.Init.HwFlowCtl = UART_HWCONTROL_NONE;
  huart5.Init.OverSampling = UART_OVERSAMPLING_16;
  huart5.Init.OneBitSampling = UART_ONE_BIT_SAMPLE_DISABLE;
  huart5.AdvancedInit.AdvFeatureInit = UART_ADVFEATURE_RXOVERRUNDISABLE_INIT;
  huart5.AdvancedInit.OverrunDisable = UART_ADVFEATURE_OVERRUN_DISABLE;
  if (HAL_UART_Init(&huart5) != HAL_OK)
  {
    Error_Handler();
  }

}

static void MX_UART7_Init(void)
{

  huart7.Instance = UART7;
  huart7.Init.BaudRate = 115200;
  huart7.Init.WordLength = UART_WORDLENGTH_8B;
  huart7.Init.StopBits = UART_STOPBITS_1;
  huart7.Init.Parity = UART_PARITY_NONE;
  huart7.Init.Mode = UART_MODE_TX_RX;
  huart7.Init.HwFlowCtl = UART_HWCONTROL_NONE;
  huart7.Init.OverSampling = UART_OVERSAMPLING_16;
  huart7.Init.OneBitSampling = UART_ONE_BIT_SAMPLE_DISABLE;
  huart7.AdvancedInit.AdvFeatureInit = UART_ADVFEATURE_RXOVERRUNDISABLE_INIT;
  huart7.AdvancedInit.OverrunDisable = UART_ADVFEATURE_OVERRUN_DISABLE;
  if (HAL_UART_Init(&huart7) != HAL_OK)
  {
    Error_Handler();
  }

}

static void MX_DMA_Init(void)
{

  /* DMA controller clock enable */
  __HAL_RCC_DMA2_CLK_ENABLE();
  __HAL_RCC_DMA1_CLK_ENABLE();

  /* DMA interrupt init */
  /* DMA1_Stream0_IRQn interrupt configuration */
  HAL_NVIC_SetPriority(DMA1_Stream0_IRQn, 5, 0);
  HAL_NVIC_EnableIRQ(DMA1_Stream0_IRQn);
  /* DMA1_Stream6_IRQn interrupt configuration */
  HAL_NVIC_SetPriority(DMA1_Stream6_IRQn, 5, 0);
  HAL_NVIC_EnableIRQ(DMA1_Stream6_IRQn);
  /* DMA2_Stream0_IRQn interrupt configuration */
  HAL_NVIC_SetPriority(DMA2_Stream0_IRQn, 5, 0);
  HAL_NVIC_EnableIRQ(DMA2_Stream0_IRQn);
  /* DMA2_Stream1_IRQn interrupt configuration */
  HAL_NVIC_SetPriority(DMA2_Stream1_IRQn, 5, 0);
  HAL_NVIC_EnableIRQ(DMA2_Stream1_IRQn);
  /* DMA2_Stream2_IRQn interrupt configuration */
  HAL_NVIC_SetPriority(DMA2_Stream2_IRQn, 5, 0);
  HAL_NVIC_EnableIRQ(DMA2_Stream2_IRQn);
  /* DMA2_Stream4_IRQn interrupt configuration */
  HAL_NVIC_SetPriority(DMA2_Stream4_IRQn, 5, 0);
  HAL_NVIC_EnableIRQ(DMA2_Stream4_IRQn);

}

static void MX_GPIO_Init(void)
{
  GPIO_InitTypeDef GPIO_InitStruct = {0};

  /* GPIO Ports Clock Enable */
  __HAL_RCC_GPIOE_CLK_ENABLE();
  __HAL_RCC_GPIOC_CLK_ENABLE();
  __HAL_RCC_GPIOF_CLK_ENABLE();
  __HAL_RCC_GPIOH_CLK_ENABLE();
  __HAL_RCC_GPIOA_CLK_ENABLE();
  __HAL_RCC_GPIOB_CLK_ENABLE();
  __HAL_RCC_GPIOG_CLK_ENABLE();
  __HAL_RCC_GPIOD_CLK_ENABLE();

  /*Configure GPIO pin Output Level */
  HAL_GPIO_WritePin(GPIOE, XB_SW_CS2_Pin|XB_SW_Y0_Pin|XB_SW_Y1_Pin|XB_SW_Y2_Pin
                          |XB_SW_CS0_Pin|XB_SW_CS1_Pin|XB_SW_X0_Pin|XB_SW_X1_Pin
                          |XB_SW_X2_Pin|XB_SW_X3_Pin, GPIO_PIN_RESET);

  /*Configure GPIO pin Output Level */
  HAL_GPIO_WritePin(GPIOF, XB_SW_STB_Pin|OSCOPE_TRIG1_Pin, GPIO_PIN_RESET);

  /*Configure GPIO pin Output Level */
  HAL_GPIO_WritePin(XB_SW_DATA_GPIO_Port, XB_SW_DATA_Pin, GPIO_PIN_RESET);

  /*Configure GPIO pin Output Level */
  HAL_GPIO_WritePin(GPIOA, OSCOPE_TRIG2_Pin|OSCOPE_TRIG3_Pin|XB_3_PRES_N_Pin, GPIO_PIN_RESET);

  /*Configure GPIO pin Output Level */
  HAL_GPIO_WritePin(GPIOB, GREEN_LED_Pin|SD_CS_Pin|RED_LED_Pin|I2C_EXP_RESET_N_Pin
                          |BLUE_LED_Pin, GPIO_PIN_RESET);

  /*Configure GPIO pin Output Level */
  HAL_GPIO_WritePin(GPIOG, DTMF_TOE0_Pin|DTMF_TOE1_Pin, GPIO_PIN_RESET);

  /*Configure GPIO pin Output Level */
  HAL_GPIO_WritePin(XB_SW_RESET_GPIO_Port, XB_SW_RESET_Pin, GPIO_PIN_RESET);

  /*Configure GPIO pins : XB_SW_CS2_Pin XB_SW_Y0_Pin XB_SW_Y1_Pin XB_SW_Y2_Pin
                           XB_SW_CS0_Pin XB_SW_CS1_Pin XB_SW_X0_Pin XB_SW_X1_Pin
                           XB_SW_X2_Pin XB_SW_X3_Pin */
  GPIO_InitStruct.Pin = XB_SW_CS2_Pin|XB_SW_Y0_Pin|XB_SW_Y1_Pin|XB_SW_Y2_Pin
                          |XB_SW_CS0_Pin|XB_SW_CS1_Pin|XB_SW_X0_Pin|XB_SW_X1_Pin
                          |XB_SW_X2_Pin|XB_SW_X3_Pin;
  GPIO_InitStruct.Mode = GPIO_MODE_OUTPUT_PP;
  GPIO_InitStruct.Pull = GPIO_NOPULL;
  GPIO_InitStruct.Speed = GPIO_SPEED_FREQ_LOW;
  HAL_GPIO_Init(GPIOE, &GPIO_InitStruct);

  /*Configure GPIO pin : USER_BUTTON_Pin */
  GPIO_InitStruct.Pin = USER_BUTTON_Pin;
  GPIO_InitStruct.Mode = GPIO_MODE_INPUT;
  GPIO_InitStruct.Pull = GPIO_NOPULL;
  HAL_GPIO_Init(USER_BUTTON_GPIO_Port, &GPIO_InitStruct);

  /*Configure GPIO pins : ATTEN0_Pin ATTEN1_Pin ATTEN2_Pin ATTEN3_Pin */
  GPIO_InitStruct.Pin = ATTEN0_Pin|ATTEN1_Pin|ATTEN2_Pin|ATTEN3_Pin;
  GPIO_InitStruct.Mode = GPIO_MODE_INPUT;
  GPIO_InitStruct.Pull = GPIO_PULLDOWN;
  HAL_GPIO_Init(GPIOF, &GPIO_InitStruct);

  /*Configure GPIO pins : XB_SW_STB_Pin OSCOPE_TRIG1_Pin */
  GPIO_InitStruct.Pin = XB_SW_STB_Pin|OSCOPE_TRIG1_Pin;
  GPIO_InitStruct.Mode = GPIO_MODE_OUTPUT_PP;
  GPIO_InitStruct.Pull = GPIO_NOPULL;
  GPIO_InitStruct.Speed = GPIO_SPEED_FREQ_LOW;
  HAL_GPIO_Init(GPIOF, &GPIO_InitStruct);

  /*Configure GPIO pin : XB_SW_DATA_Pin */
  GPIO_InitStruct.Pin = XB_SW_DATA_Pin;
  GPIO_InitStruct.Mode = GPIO_MODE_OUTPUT_PP;
  GPIO_InitStruct.Pull = GPIO_NOPULL;
  GPIO_InitStruct.Speed = GPIO_SPEED_FREQ_LOW;
  HAL_GPIO_Init(XB_SW_DATA_GPIO_Port, &GPIO_InitStruct);

  /*Configure GPIO pins : OSCOPE_TRIG2_Pin OSCOPE_TRIG3_Pin XB_3_PRES_N_Pin */
  GPIO_InitStruct.Pin = OSCOPE_TRIG2_Pin|OSCOPE_TRIG3_Pin|XB_3_PRES_N_Pin;
  GPIO_InitStruct.Mode = GPIO_MODE_OUTPUT_PP;
  GPIO_InitStruct.Pull = GPIO_NOPULL;
  GPIO_InitStruct.Speed = GPIO_SPEED_FREQ_LOW;
  HAL_GPIO_Init(GPIOA, &GPIO_InitStruct);

  /*Configure GPIO pins : GREEN_LED_Pin SD_CS_Pin RED_LED_Pin I2C_EXP_RESET_N_Pin
                           BLUE_LED_Pin */
  GPIO_InitStruct.Pin = GREEN_LED_Pin|SD_CS_Pin|RED_LED_Pin|I2C_EXP_RESET_N_Pin
                          |BLUE_LED_Pin;
  GPIO_InitStruct.Mode = GPIO_MODE_OUTPUT_PP;
  GPIO_InitStruct.Pull = GPIO_NOPULL;
  GPIO_InitStruct.Speed = GPIO_SPEED_FREQ_LOW;
  HAL_GPIO_Init(GPIOB, &GPIO_InitStruct);

  /*Configure GPIO pins : DTMF_STB0_Pin DTMF_STB1_Pin */
  GPIO_InitStruct.Pin = DTMF_STB0_Pin|DTMF_STB1_Pin;
  GPIO_InitStruct.Mode = GPIO_MODE_INPUT;
  GPIO_InitStruct.Pull = GPIO_NOPULL;
  HAL_GPIO_Init(GPIOF, &GPIO_InitStruct);

  /*Configure GPIO pins : DTMF_TOE0_Pin DTMF_TOE1_Pin */
  GPIO_InitStruct.Pin = DTMF_TOE0_Pin|DTMF_TOE1_Pin;
  GPIO_InitStruct.Mode = GPIO_MODE_OUTPUT_PP;
  GPIO_InitStruct.Pull = GPIO_NOPULL;
  GPIO_InitStruct.Speed = GPIO_SPEED_FREQ_LOW;
  HAL_GPIO_Init(GPIOG, &GPIO_InitStruct);

  /*Configure GPIO pins : ATTEN4_Pin ATTEN5_Pin ATTEN6_Pin ATTEN7_Pin
                           DTMF_0_Pin DTMF_2_Pin DTMF_3_Pin */
  GPIO_InitStruct.Pin = ATTEN4_Pin|ATTEN5_Pin|ATTEN6_Pin|ATTEN7_Pin
                          |DTMF_0_Pin|DTMF_2_Pin|DTMF_3_Pin;
  GPIO_InitStruct.Mode = GPIO_MODE_INPUT;
  GPIO_InitStruct.Pull = GPIO_PULLDOWN;
  HAL_GPIO_Init(GPIOG, &GPIO_InitStruct);

  /*Configure GPIO pin : SD_PRESENT_N_Pin */
  GPIO_InitStruct.Pin = SD_PRESENT_N_Pin;
  GPIO_InitStruct.Mode = GPIO_MODE_INPUT;
  GPIO_InitStruct.Pull = GPIO_PULLUP;
  HAL_GPIO_Init(SD_PRESENT_N_GPIO_Port, &GPIO_InitStruct);

  /*Configure GPIO pin : XB_SW_RESET_Pin */
  GPIO_InitStruct.Pin = XB_SW_RESET_Pin;
  GPIO_InitStruct.Mode = GPIO_MODE_OUTPUT_PP;
  GPIO_InitStruct.Pull = GPIO_NOPULL;
  GPIO_InitStruct.Speed = GPIO_SPEED_FREQ_LOW;
  HAL_GPIO_Init(XB_SW_RESET_GPIO_Port, &GPIO_InitStruct);

  /*Configure GPIO pin : DTMF_1_Pin */
  GPIO_InitStruct.Pin = DTMF_1_Pin;
  GPIO_InitStruct.Mode = GPIO_MODE_INPUT;
  GPIO_InitStruct.Pull = GPIO_NOPULL;
  HAL_GPIO_Init(DTMF_1_GPIO_Port, &GPIO_InitStruct);

}

void StartDefaultTask(void *argument)
{
  /* USER CODE BEGIN 5 */
  /* initialization hook */
  Top_init();
  /* Infinite loop */
  for(;;)
  {
    /* default task hook */
    Top_default_task();
  }
  /* USER CODE END 5 */
}

void HAL_TIM_PeriodElapsedCallback(TIM_HandleTypeDef *htim)
{
  if (htim->Instance == TIM10) {
    HAL_IncTick();
  }
}

void Error_Handler(void)
{
  /* USER CODE BEGIN Error_Handler_Debug */
  /* Turn red LED ON */

  /* User can add his own implementation to report the HAL error return state */

  __disable_irq();
  while (1)
  {
	  volatile uint32_t counter;
	  HAL_GPIO_TogglePin(RED_LED_GPIO_Port, RED_LED_Pin);
	  counter = 10000000;
	  while(counter--);

  }
  /* USER CODE END Error_Handler_Debug */
}
